# PSC_PSC_00400000h register map
Vendor: Texas Instruments
Peripheral module from a debugger description file (folder AM275x).
Registers are 32-bit, read-only, reset 0x0 unless marked. A register's access mark holds for its fields unless they carry their own. Offsets are as the file gives them; lines under a group give offsets from that group; [hi:lo] are bit positions; {n}, {i} and the like mark numbered series; 'fields as' and 'values as' point back to an identical list; <NAME> marks a mode.

## psc
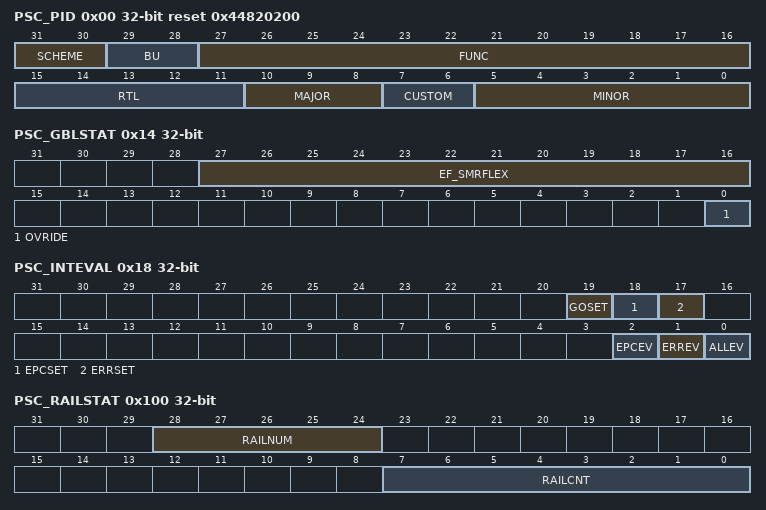
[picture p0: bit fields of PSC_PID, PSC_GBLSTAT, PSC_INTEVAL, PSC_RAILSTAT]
0x00 PSC_PID reset 0x44820200 — The peripheral identification register is a constant register that contains the ID and ID revision number for that module. The PID stores version information used to identify the module. All bits within this register are read-only (writes have no effect) meaning that the values within this register should be hard-coded with the appropriate values and must not change from their hard-coded values.
  [31:30] SCHEME — PID register scheme Reset Source: chip_rst.chip_1_rst_n
  [29:28] BU — Business Unit Reset Source: chip_rst.chip_1_rst_n
  [27:16] FUNC — Module ID Reset Source: chip_rst.chip_1_rst_n
  [15:11] RTL — RTL revision. Will vary depending on release Reset Source: chip_rst.chip_1_rst_n
  [10:8] MAJOR — Major revision Reset Source: chip_rst.chip_1_rst_n
  [7:6] CUSTOM — Custom Reset Source: chip_rst.chip_1_rst_n
  [5:0] MINOR — Minor revision Reset Source: chip_rst.chip_1_rst_n
0x14 PSC_GBLSTAT — This register shows the PSC global status.
  [27:16] EF_SMRFLEX — Smart reflex class0 bits Reset Source: chip_rst.chip_1_rst_n
  [0] OVRIDE — PSC Override Status Reset Source: chip_rst.chip_1_rst_n
0x18 PSC_INTEVAL wo — This register has no storage. Read from this register returns 0.
  [19] GOSET — GOSTAT Interrupt Set Reset Source: chip_rst.chip_1_rst_n
  [18] EPCSET — External Power Control Interrupt Set Reset Source: chip_rst.chip_1_rst_n
  [17] ERRSET — Combined Interrupt Set Reset Source: chip_rst.chip_1_rst_n
  [2] EPCEV — External Power Control Interrupt Set Reset Source: chip_rst.chip_1_rst_n
  [1] ERREV — Re_evaluate Error Interrupt Reset Source: chip_rst.chip_1_rst_n
  [0] ALLEV — Re_evaluate combined PSC interrupt 0 Write of 0 has no effect1 Re-evaluate the combined PSC interrupt PSC_ALLINT
0x40 PSC_MERRPR_j — This register records pending error conditions for all modules. Each bit represents one module (index 0 for modules 0-31, index 1 for modules 32-63, etc.).
  [31:0] M — Records pending error conditions. Each bit n represents a module. Reset Source: chip_rst.chip_1_rst_n
0x50 PSC_MERRCR_j access not given — This register has no storage. Read from this register returns 0. Each bit represents one module (index 0 for modules 0-31, index 1 for modules 32-63, etc.).
  [31:0] M — Write of 1 clears the corresponding MERRPR bit. Reset Source: chip_rst.chip_1_rst_n (access W1TC)
0x60 PSC_PERRPR — This register records pending error conditions for each power domain. Each bit represents one domain (index 0 for domains 0-31, index 1 for domains 32-63, etc.).
  [31:0] P — Power Domain n Error Condition. Each bit n represents a power domain. Reset Source: chip_rst.chip_1_rst_n
0x68 PSC_PERRCR access not given — This register has no storage. Read from this register returns 0. Each bit represents one domain (index 0 for domains 0-31, index 1 for domains 32-63, etc.).
  [31:0] P — Write of 1 clears the corresponding PERRPR bit. Reset Source: chip_rst.chip_1_rst_n (access W1TC)
0x70 PSC_EPCPR — This register records pending external power control conditions. Each bit represents one domain (index 0 for domains 0-31, index 1 for domains 32-63, etc.).
  [31:0] EPC — External Power Control Intervention Request for Power Domain n Reset Source: chip_rst.chip_1_rst_n
0x78 PSC_EPCCR access not given — This register has no storage. Read from this register returns 0. Each bit represents one domain (index 0 for domains 0-31, index 1 for domains 32-63, etc.).
  [31:0] EPC — Write of 1 clears the corresponding EPCPR bit Reset Source: chip_rst.chip_1_rst_n (access W1TC)
0x100 PSC_RAILSTAT — This register is a read-only and shows the current rail requestor whose request is being granted and the current value of the counter associated with this requestor.
  [28:24] RAILNUM — Indicates Current Rail Requestor being processed by GPSC Reset Source: chip_rst.chip_1_rst_n
  [7:0] RAILCNT — Indicates the current rail counter value Reset Source: chip_rst.chip_1_rst_n
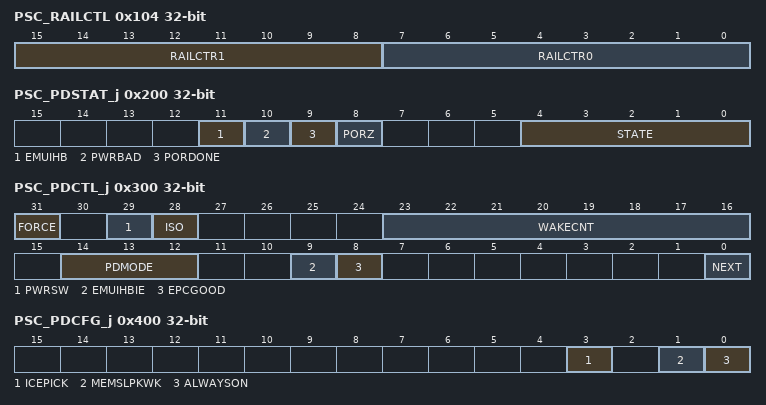
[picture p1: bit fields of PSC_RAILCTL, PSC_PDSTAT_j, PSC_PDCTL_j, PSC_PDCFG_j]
0x104 PSC_RAILCTL rw — This register is user programmable. It holds the counter values for rail counter. User can select one of the two counter values to be used for each power domain (see RAILSEL register).
  [15:8] RAILCTR1 — Rail Counter Value 1 Reset Source: chip_rst.chip_1_rst_n
  [7:0] RAILCTR0 — Rail Counter Value 0 Reset Source: chip_rst.chip_1_rst_n
0x108 PSC_RAILSEL rw — User can use this register to select the counter value (RAILCTL) for each power domain.
  [31:0] P — Rail Counter Select for Power Domain Reset Source: chip_rst.chip_1_rst_n
0x120 PSC_PTCMD access not given — This is a pseudo-command register with no actual storage. Reads return 0. One bit for each power domain (index 0 for domains 0-31, index 1 for domains 32-63, etc.).
  [31:0] GO — Power Domain n GO Transition 0 Write of 0 has no effect1 Sets corresponding PTSTAT.GOSTAT field which causes PSC hardware to evaluate PDCTL.NEXT and MDCTL.NEXT for this domain. (access W1TS)
0x128 PSC_PTSTAT — This is a status register. One bit for each power domain (index 0 for domains 0-31, index 1 for domains 32-63, etc.).
  [31:0] GOSTAT — Power Domain n Transition Command Status 0 No transitions in progress in Power Domain1 Power Domain Transition in progress. Either the power domain is transitioning, or modules on this domain are transitioning.
0x200 PSC_PDSTAT_j — This is a status register. One register per power domain. Each register contains the status for the given power domain.
  [11] EMUIHB — Emulation Alters Domain State Reset Source: chip_rst.chip_1_rst_n
  [10] PWRBAD — Power Bad error Reset Source: chip_rst.chip_1_rst_n
  [9] PORDONE — POR Done Input Status Reset Source: chip_rst.chip_1_rst_n
  [8] PORZ — PORz output actual status Reset Source: chip_rst.chip_1_rst_n
  [4:0] STATE — Current Power Domain State 0 Power domain is off1 Power domain is on
0x300 PSC_PDCTL_j rw — This is a control register. One register per power domain.
  [31] FORCE — Force Bit Reset Source: chip_rst.chip_1_rst_n
  [29] PWRSW — Power shorting Switch Control Reset Source: chip_rst.chip_1_rst_n
  [28] ISO — Isolation Cell control Reset Source: chip_rst.chip_1_rst_n
  [23:16] WAKECNT — RAM wake count delay value Reset Source: chip_rst.chip_1_rst_n
  [14:12] PDMODE — Power Down mode 0 Core Off, RAM Array Off, RAM Periphery Off8 Core Retention, RAM Array Off, RAM Periphery Off9 Core Retention, RAM Array Retention, RAM Periphery Off10 Core On, RAM Array Retention, RAM Periphery Off11 Core On, RAM Array Retention, RAM Periphery On15 Core On, RAM Array On, RAM Periphery On
  [9] EMUIHBIE — Emulation alters domain state 0 Not enabled1 Interrupt enabled
  [8] EPCGOOD — External Power Control Power Good Indication Reset Source: chip_rst.chip_1_rst_n
  [0] NEXT — User_Desired Next Power Domain State 0 Off1 On
0x400 PSC_PDCFG_j — This is a status register. It shows PSC settings for easy debug.
  [3] ICEPICK — Icepick support 0 This domain does not have IcePick support1 This domain has IcePick support because one or more of its LPSCs have IcePick support
  [1] MEMSLPKWK — Memory sleep-wake domain Reset Source: chip_rst.chip_1_rst_n
  [0] ALWAYSON — Always on power domain 0 This domain is not an AlwaysON power domain1 This domain is an AlwaysON power domain
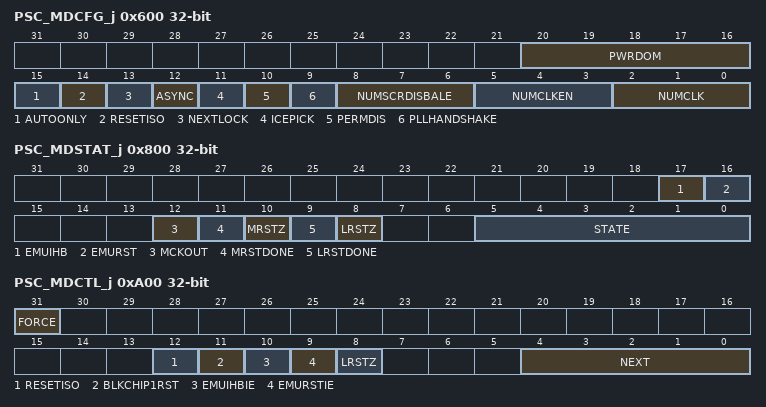
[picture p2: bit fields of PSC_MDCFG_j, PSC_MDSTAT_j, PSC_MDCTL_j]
0x600 PSC_MDCFG_j — This is a constant register showing some PSC settings for easy debug. This register is read only.
  [20:16] PWRDOM — Indicates which power domain this module belongs to Reset Source: chip_rst.chip_1_rst_n
  [15] AUTOONLY — 0: This LPSC supports all modes, 1: This LPSC supports Enable, AutoSleep or AutoWake only Reset Source: chip_rst.chip_1_rst_n
  [14] RESETISO — 0: This LPSC does not support Reset Isolation, 1: This LPSC supports Reset Isolation Reset Source: chip_rst.chip_1_rst_n
  [13] NEXTLOCK — 0: MDCTL.NEXT field is writable, 1: MDCTL.NEXT field is locked Reset Source: chip_rst.chip_1_rst_n
  [12] ASYNC — Async Lpsc Reset Source: chip_rst.chip_1_rst_n
  [11] ICEPICK — IcePick support Reset Source: chip_rst.chip_1_rst_n
  [10] PERMDIS — Permanently disable Reset Source: chip_rst.chip_1_rst_n
  [9] PLLHANDSHAKE — RTL parameter PLL_HANDSHAKE Reset Source: chip_rst.chip_1_rst_n
  [8:6] NUMSCRDISBALE — Number of PWR_SCR_DISABLE interfaces required on LPSC Reset Source: chip_rst.chip_1_rst_n
  [5:3] NUMCLKEN — Number of PWR_CLK_EN interfaces required on LPSC Reset Source: chip_rst.chip_1_rst_n
  [2:0] NUMCLK — Number of PWR_CLKSTOP interfaces required on LPSC Reset Source: chip_rst.chip_1_rst_n
0x800 PSC_MDSTAT_j — This register shows the status of each module. Requires one register per module on the device.
  [17] EMUIHB — Emulation Alters Module State. Inhibits Module Inactive or Force Module Active. 0 No emulation altering user-desired module state1 Emulation alters user-desired module state
  [16] EMURST — Emulation Alters Reset 0 No emulation altering user-desired reset1 Emulation has altered module reset to be different from what user desires
  [12] MCKOUT — Actual modclk output to module 0 modclk gated1 modclk on
  [11] MRSTDONE — Module reset initialization done status 0 module reset initialization not done1 module reset initialization done
  [10] MRSTZ — Module reset actual status 0 module reset modrst_po* asserted1 module reset modrst_po* de-asserted
  [9] LRSTDONE — Module local reset initialization done status 0 local reset initialization not done1 local reset initialization done
  [8] LRSTZ — Module local reset actual status 0 local reset mod_lrst_po* asserted1 local reset mod_lrst_po* de-asserted
  [5:0] STATE — These bits indicate the current module stateValues 0x0 - 0x5 = Key StatesValues 0x21 - 0x2B = Transitional StatesOther Values = Reserved 4 AutoSleep5 AutoWake2 Disable3 Enable0 SwRstDisable1 SyncRst33 Disable Clk On34 Disable In-Prog (waiting for clkstop_ack = 1)35 Retry Disable (new vbus_req, retry--give clkstop_req = 1 again)36 Enable In-Prog37 Sleep In-Prog38 ClockOn (from SwRstDisable to SyncRst)39 ClockOff (from SyncRst to SwRstDisable)40 ClockOn (from Disable to DisableClkOn)41 ClockOff (from DisableClkOn to Disable)42 ClockOn (from AutoSleep/Wake to Sleep In- Prog)43 ClockOff (from DisableClkOn or Sleep In- Prog to AutoSleep/Wake)Other Reserveds
0xA00 PSC_MDCTL_j rw — This register provides specific control for the individual module. One register per module on the device.
  [31] FORCE — Force Bit 0 No force1 Force
  [12] RESETISO — Reset Isolation 0 No reset isolation1 Enable reset isolation
  [11] BLKCHIP1RST — Block Chip_1_Reset Reset Source: chip_rst.chip_1_rst_n
  [10] EMUIHBIE — Emulation Alters Module State. Inhibits Module Inactive or Force Module Active. 0 Not enabled1 Interrupt enabled
  [9] EMURSTIE — Emulation Alter Reset Interrupt Enable 0 Not enabled1 Interrupt enabled
  [8] LRSTZ — Module local reset control 0 assert local reset1 de-assert local reset
  [4:0] NEXT — Module Next StateOnly key states can be selected in this field.If a Reserved value is programmed into MDCTL.NEXT, hardware will internally force the state to SwRstDisable.If MDCFG.PERMDIS = 1, the module must remain in SwRstDisable after hardware places it in SwRstDisable state. The user is allowed to write this field but hardware ignores this field and always passes along MDCTL.NEXT = SwRstDisable. 4 AutoSleep5 AutoWake2 Disable3 Enable0 SwRstDisable1 SyncRstOther Reserveds
